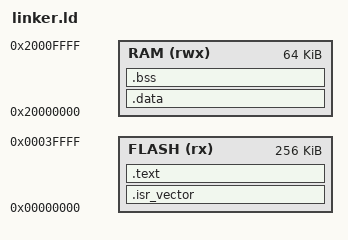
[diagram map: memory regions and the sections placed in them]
/* QEMU lm3s6965evb: 256K flash at 0x00000000, 64K SRAM at 0x20000000. */
ENTRY(Reset_Handler)

MEMORY
{
    FLASH (rx)  : ORIGIN = 0x00000000, LENGTH = 256K
    RAM   (rwx) : ORIGIN = 0x20000000, LENGTH = 64K
}

__stack_top__ = ORIGIN(RAM) + LENGTH(RAM);

SECTIONS
{
    .isr_vector :
    {
        . = ALIGN(4);
        KEEP(*(.isr_vector))
        . = ALIGN(4);
    } > FLASH

    .text :
    {
        . = ALIGN(4);
        *(.text*)
        *(.rodata*)
        . = ALIGN(4);
        __etext = .;
    } > FLASH

    .data : AT (__etext)
    {
        . = ALIGN(4);
        _sdata = .;
        *(.data*)
        . = ALIGN(4);
        _edata = .;
    } > RAM
    __sidata = LOADADDR(.data);

    .bss (NOLOAD) :
    {
        . = ALIGN(4);
        _sbss = .;
        *(.bss*)
        *(COMMON)
        . = ALIGN(4);
        _ebss = .;
    } > RAM

    /DISCARD/ :
    {
        *(.ARM.exidx*)
        *(.ARM.extab*)
        *(.eh_frame*)
        *(.comment*)
    }
}
